AUTOSAR XML (schema 4-3-0)
package /App_CAN_TX
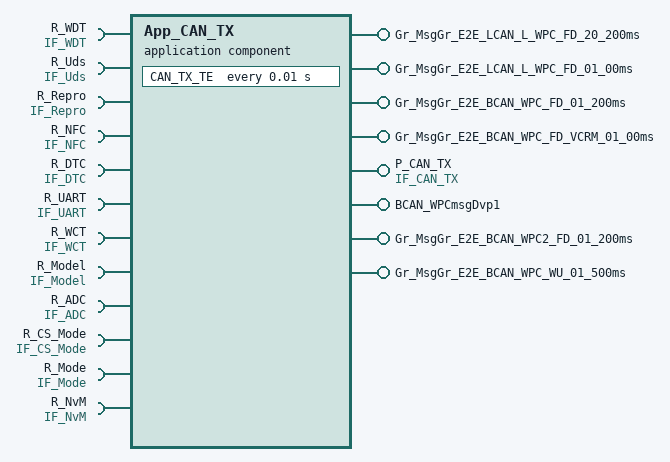
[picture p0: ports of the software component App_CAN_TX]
  application sw component type App_CAN_TX
    11 x require port:
      R_WDT: nonqueued-receiver-com-spec=WDT_STR, required-interface=IF_WDT
      R_Uds: nonqueued-receiver-com-spec=Uds_STR, required-interface=IF_Uds
      R_Repro: nonqueued-receiver-com-spec=Repro_STR, required-interface=IF_Repro
      R_NFC: nonqueued-receiver-com-spec=NFC_STR, required-interface=IF_NFC
      R_DTC: nonqueued-receiver-com-spec=DTC_STR, required-interface=IF_DTC
      R_UART: nonqueued-receiver-com-spec=UART_STR, required-interface=IF_UART
      R_WCT: nonqueued-receiver-com-spec=WCT_STR, required-interface=IF_WCT
      R_Model: nonqueued-receiver-com-spec=Model_STR, required-interface=IF_Model
      R_ADC: nonqueued-receiver-com-spec=ADC_STR, required-interface=IF_ADC
      R_CS_Mode: required-com-specs=[ModeInit, NvMInit, ApplicationInit], required-interface=IF_CS_Mode
      R_Mode: nonqueued-receiver-com-spec=Mode_STR, required-interface=IF_Mode
    6 x provide port:
      Gr_MsgGr_E2E_LCAN_L_WPC_FD_20_200ms: nonqueued-sender-com-spec=data-element=MsgGr_E2E_LCAN_L_WPC_FD_20_200ms, provided-interface=Gr_MsgGr_E2E_LCAN_L_WPC_FD_20_200ms
      Gr_MsgGr_E2E_LCAN_L_WPC_FD_01_00ms: nonqueued-sender-com-spec=data-element=MsgGr_E2E_LCAN_L_WPC_FD_01_00ms, provided-interface=Gr_MsgGr_E2E_LCAN_L_WPC_FD_01_00ms
      Gr_MsgGr_E2E_BCAN_WPC_FD_01_200ms: nonqueued-sender-com-spec=data-element=MsgGr_E2E_BCAN_WPC_FD_01_200ms, provided-interface=Gr_MsgGr_E2E_BCAN_WPC_FD_01_200ms
      Gr_MsgGr_E2E_BCAN_WPC_FD_VCRM_01_00ms: nonqueued-sender-com-spec=data-element=MsgGr_E2E_BCAN_WPC_FD_VCRM_01_00ms, provided-interface=Gr_MsgGr_E2E_BCAN_WPC_FD_VCRM_01_00ms
      P_CAN_TX: provided-interface=IF_CAN_TX
      BCAN_WPCmsgDvp1: provided-interface=BCAN_WPCmsgDvp1
        provided-com-specs:
          data-element=WPCmsgDvp1DataByte09, network-representation=compu-method=ISignal_BCAN_WPCmsgDvp1_WPCmsgDvp1DataByte09
          data-element=WPCmsgDvp1DataByte08, network-representation=compu-method=ISignal_BCAN_WPCmsgDvp1_WPCmsgDvp1DataByte08
          data-element=WPCmsgDvp1DataByte07, network-representation=compu-method=ISignal_BCAN_WPCmsgDvp1_WPCmsgDvp1DataByte07
          data-element=WPCmsgDvp1DataByte06, network-representation=compu-method=ISignal_BCAN_WPCmsgDvp1_WPCmsgDvp1DataByte06
          data-element=WPCmsgDvp1DataByte49, network-representation=compu-method=ISignal_BCAN_WPCmsgDvp1_WPCmsgDvp1DataByte49
          data-element=WPCmsgDvp1DataByte05, network-representation=compu-method=ISignal_BCAN_WPCmsgDvp1_WPCmsgDvp1DataByte05
          data-element=WPCmsgDvp1DataByte51, network-representation=compu-method=ISignal_BCAN_WPCmsgDvp1_WPCmsgDvp1DataByte51
          data-element=WPCmsgDvp1DataByte50, network-representation=compu-method=ISignal_BCAN_WPCmsgDvp1_WPCmsgDvp1DataByte50
          data-element=WPCmsgDvp1DataByte59, network-representation=compu-method=ISignal_BCAN_WPCmsgDvp1_WPCmsgDvp1DataByte59
          data-element=WPCmsgDvp1DataByte15, network-representation=compu-method=ISignal_BCAN_WPCmsgDvp1_WPCmsgDvp1DataByte15
          data-element=WPCmsgDvp1DataByte58, network-representation=compu-method=ISignal_BCAN_WPCmsgDvp1_WPCmsgDvp1DataByte58
          data-element=WPCmsgDvp1DataByte14, network-representation=compu-method=ISignal_BCAN_WPCmsgDvp1_WPCmsgDvp1DataByte14
          data-element=WPCmsgDvp1DataByte57, network-representation=compu-method=ISignal_BCAN_WPCmsgDvp1_WPCmsgDvp1DataByte57
          data-element=WPCmsgDvp1DataByte13, network-representation=compu-method=ISignal_BCAN_WPCmsgDvp1_WPCmsgDvp1DataByte13
          data-element=WPCmsgDvp1DataByte56, network-representation=compu-method=ISignal_BCAN_WPCmsgDvp1_WPCmsgDvp1DataByte56
          data-element=WPCmsgDvp1DataByte12, network-representation=compu-method=ISignal_BCAN_WPCmsgDvp1_WPCmsgDvp1DataByte12
          data-element=WPCmsgDvp1DataByte55, network-representation=compu-method=ISignal_BCAN_WPCmsgDvp1_WPCmsgDvp1DataByte55
          data-element=WPCmsgDvp1DataByte11, network-representation=compu-method=ISignal_BCAN_WPCmsgDvp1_WPCmsgDvp1DataByte11
          data-element=WPCmsgDvp1DataByte54, network-representation=compu-method=ISignal_BCAN_WPCmsgDvp1_WPCmsgDvp1DataByte54
          data-element=WPCmsgDvp1DataByte10, network-representation=compu-method=ISignal_BCAN_WPCmsgDvp1_WPCmsgDvp1DataByte10
          data-element=WPCmsgDvp1DataByte53, network-representation=compu-method=ISignal_BCAN_WPCmsgDvp1_WPCmsgDvp1DataByte53
          data-element=WPCmsgDvp1DataByte52, network-representation=compu-method=ISignal_BCAN_WPCmsgDvp1_WPCmsgDvp1DataByte52
          data-element=WPCmsgDvp1DataByte39, network-representation=compu-method=ISignal_BCAN_WPCmsgDvp1_WPCmsgDvp1DataByte39
          data-element=WPCmsgDvp1DataByte38, network-representation=compu-method=ISignal_BCAN_WPCmsgDvp1_WPCmsgDvp1DataByte38
          data-element=WPCmsgDvp1DataByte40, network-representation=compu-method=ISignal_BCAN_WPCmsgDvp1_WPCmsgDvp1DataByte40
          data-element=WPCmsgDvp1DataByte48, network-representation=compu-method=ISignal_BCAN_WPCmsgDvp1_WPCmsgDvp1DataByte48
          data-element=WPCmsgDvp1DataByte04, network-representation=compu-method=ISignal_BCAN_WPCmsgDvp1_WPCmsgDvp1DataByte04
          data-element=WPCmsgDvp1DataByte47, network-representation=compu-method=ISignal_BCAN_WPCmsgDvp1_WPCmsgDvp1DataByte47
          data-element=WPCmsgDvp1DataByte03, network-representation=compu-method=ISignal_BCAN_WPCmsgDvp1_WPCmsgDvp1DataByte03
          data-element=WPCmsgDvp1DataByte46, network-representation=compu-method=ISignal_BCAN_WPCmsgDvp1_WPCmsgDvp1DataByte46
          data-element=WPCmsgDvp1DataByte02, network-representation=compu-method=ISignal_BCAN_WPCmsgDvp1_WPCmsgDvp1DataByte02
          data-element=WPCmsgDvp1DataByte45, network-representation=compu-method=ISignal_BCAN_WPCmsgDvp1_WPCmsgDvp1DataByte45
          data-element=WPCmsgDvp1DataByte01, network-representation=compu-method=ISignal_BCAN_WPCmsgDvp1_WPCmsgDvp1DataByte01
          data-element=WPCmsgDvp1DataByte44, network-representation=compu-method=ISignal_BCAN_WPCmsgDvp1_WPCmsgDvp1DataByte44
          data-element=WPCmsgDvp1DataByte00, network-representation=compu-method=ISignal_BCAN_WPCmsgDvp1_WPCmsgDvp1DataByte00
          data-element=WPCmsgDvp1DataByte43, network-representation=compu-method=ISignal_BCAN_WPCmsgDvp1_WPCmsgDvp1DataByte43
          data-element=WPCmsgDvp1DataByte42, network-representation=compu-method=ISignal_BCAN_WPCmsgDvp1_WPCmsgDvp1DataByte42
          data-element=WPCmsgDvp1DataByte41, network-representation=compu-method=ISignal_BCAN_WPCmsgDvp1_WPCmsgDvp1DataByte41
          data-element=WPCmsgDvp1DataByte29, network-representation=compu-method=ISignal_BCAN_WPCmsgDvp1_WPCmsgDvp1DataByte29
          data-element=WPCmsgDvp1DataByte28, network-representation=compu-method=ISignal_BCAN_WPCmsgDvp1_WPCmsgDvp1DataByte28
          data-element=WPCmsgDvp1DataByte27, network-representation=compu-method=ISignal_BCAN_WPCmsgDvp1_WPCmsgDvp1DataByte27
          data-element=WPCmsgDvp1DataByte37, network-representation=compu-method=ISignal_BCAN_WPCmsgDvp1_WPCmsgDvp1DataByte37
          data-element=WPCmsgDvp1DataByte36, network-representation=compu-method=ISignal_BCAN_WPCmsgDvp1_WPCmsgDvp1DataByte36
          data-element=WPCmsgDvp1DataByte35, network-representation=compu-method=ISignal_BCAN_WPCmsgDvp1_WPCmsgDvp1DataByte35
          data-element=WPCmsgDvp1DataByte34, network-representation=compu-method=ISignal_BCAN_WPCmsgDvp1_WPCmsgDvp1DataByte34
          data-element=WPCmsgDvp1DataByte33, network-representation=compu-method=ISignal_BCAN_WPCmsgDvp1_WPCmsgDvp1DataByte33
          data-element=WPCmsgDvp1DataByte32, network-representation=compu-method=ISignal_BCAN_WPCmsgDvp1_WPCmsgDvp1DataByte32
          data-element=WPCmsgDvp1DataByte31, network-representation=compu-method=ISignal_BCAN_WPCmsgDvp1_WPCmsgDvp1DataByte31
          data-element=WPCmsgDvp1DataByte30, network-representation=compu-method=ISignal_BCAN_WPCmsgDvp1_WPCmsgDvp1DataByte30
          data-element=WPCmsgDvp1DataByte19, network-representation=compu-method=ISignal_BCAN_WPCmsgDvp1_WPCmsgDvp1DataByte19
          data-element=WPCmsgDvp1DataByte18, network-representation=compu-method=ISignal_BCAN_WPCmsgDvp1_WPCmsgDvp1DataByte18
          data-element=WPCmsgDvp1DataByte17, network-representation=compu-method=ISignal_BCAN_WPCmsgDvp1_WPCmsgDvp1DataByte17
          data-element=WPCmsgDvp1DataByte16, network-representation=compu-method=ISignal_BCAN_WPCmsgDvp1_WPCmsgDvp1DataByte16
          data-element=WPCmsgDvp1DataByte62, network-representation=compu-method=ISignal_BCAN_WPCmsgDvp1_WPCmsgDvp1DataByte62
          data-element=WPCmsgDvp1DataByte61, network-representation=compu-method=ISignal_BCAN_WPCmsgDvp1_WPCmsgDvp1DataByte61
          data-element=WPCmsgDvp1DataByte60, network-representation=compu-method=ISignal_BCAN_WPCmsgDvp1_WPCmsgDvp1DataByte60
          data-element=WPCmsgDvp1DataByte26, network-representation=compu-method=ISignal_BCAN_WPCmsgDvp1_WPCmsgDvp1DataByte26
          data-element=WPCmsgDvp1DataByte25, network-representation=compu-method=ISignal_BCAN_WPCmsgDvp1_WPCmsgDvp1DataByte25
          data-element=WPCmsgDvp1DataByte24, network-representation=compu-method=ISignal_BCAN_WPCmsgDvp1_WPCmsgDvp1DataByte24
          data-element=WPCmsgDvp1DataByte23, network-representation=compu-method=ISignal_BCAN_WPCmsgDvp1_WPCmsgDvp1DataByte23
          data-element=WPCmsgDvp1DataByte22, network-representation=compu-method=ISignal_BCAN_WPCmsgDvp1_WPCmsgDvp1DataByte22
          data-element=WPCmsgDvp1DataByte21, network-representation=compu-method=ISignal_BCAN_WPCmsgDvp1_WPCmsgDvp1DataByte21
          data-element=WPCmsgDvp1DataByte20, network-representation=compu-method=ISignal_BCAN_WPCmsgDvp1_WPCmsgDvp1DataByte20
          data-element=WPCmsgDvp1DataByte63, network-representation=compu-method=ISignal_BCAN_WPCmsgDvp1_WPCmsgDvp1DataByte63
    require port R_NvM: nonqueued-receiver-com-spec=NvM_STR, required-interface=IF_NvM
    provide port Gr_MsgGr_E2E_BCAN_WPC2_FD_01_200ms: nonqueued-sender-com-spec=data-element=MsgGr_E2E_BCAN_WPC2_FD_01_200ms, provided-interface=Gr_MsgGr_E2E_BCAN_WPC2_FD_01_200ms
    provide port Gr_MsgGr_E2E_BCAN_WPC_WU_01_500ms: nonqueued-sender-com-spec=data-element=MsgGr_E2E_BCAN_WPC_WU_01_500ms, provided-interface=Gr_MsgGr_E2E_BCAN_WPC_WU_01_500ms
    behavior InternalBehavior: data-type-mapping=DataTypeMappingSet_WPC
      timing event TE_CAN_TX_TE: start-on-event=CAN_TX_TE, period=0.01
      runnable CAN_TX_TE: symbol=CAN_TX_TE_Runnable
        data-receive-point-by-arguments:
          11 x access, all with scope=COMMUNICATION-INTER-ECU:
            DRPBA_BCAN_TX_TE_R_Mode_Mode_u8_arr: accessed-variable=R_Mode.Mode_STR
            DRPBA_BCAN_TX_TE_R_ADC_u8_arr: accessed-variable=R_ADC.ADC_STR
            DRPBA_BCAN_TX_TE_R_Model_Structure: accessed-variable=R_Model.Model_STR
            DRPBA_BCAN_TX_TE_R_Repro_Structure: accessed-variable=R_Repro.Repro_STR
            DRPBA_BCAN_TX_TE_R_UART_Structure: accessed-variable=R_UART.UART_STR
            DRPBA_CAN_TX_TE_R_NFC_NFC2_STR: accessed-variable=R_NFC.NFC_STR
            DRPBA_CAN_TX_TE_R_WCT_WCT_STR_ALL: accessed-variable=R_WCT.WCT_STR
            DRPBA_CAN_TX_TE_R_DTC_DTC_STR: accessed-variable=R_DTC.DTC_STR
            DRPBA_CAN_TX_TE_R_NvM_NvM_STR: accessed-variable=R_NvM.NvM_STR
            DRPBA_CAN_TX_TE_R_Uds_Uds_STR: accessed-variable=R_Uds.Uds_STR
            DRPBA_CAN_TX_TE_R_WDT_WDT_STR: accessed-variable=R_WDT.WDT_STR
        data-send-points:
          70 x access, all with scope=COMMUNICATION-INTER-ECU:
            DSP_CAN_TX_TE_Gr_MsgGr_E2E_LCAN_L_WPC_FD_20_200ms_MsgGr_E2E_LCAN_L_WPC_FD_20_200ms: accessed-variable=Gr_MsgGr_E2E_LCAN_L_WPC_FD_20_200ms.MsgGr_E2E_LCAN_L_WPC_FD_20_200ms
            DSP_CAN_TX_TE_Gr_MsgGr_E2E_LCAN_L_WPC_FD_01_00ms_MsgGr_E2E_LCAN_L_WPC_FD_01_00ms: accessed-variable=Gr_MsgGr_E2E_LCAN_L_WPC_FD_01_00ms.MsgGr_E2E_LCAN_L_WPC_FD_01_00ms
            DSP_CAN_TX_TE_Gr_MsgGr_E2E_BCAN_WPC_FD_01_200ms_MsgGr_E2E_BCAN_WPC_FD_01_200ms: accessed-variable=Gr_MsgGr_E2E_BCAN_WPC_FD_01_200ms.MsgGr_E2E_BCAN_WPC_FD_01_200ms
            DSP_CAN_TX_TE_Gr_MsgGr_E2E_BCAN_WPC_FD_VCRM_01_00ms_MsgGr_E2E_BCAN_WPC_FD_VCRM_01_00ms: accessed-variable=Gr_MsgGr_E2E_BCAN_WPC_FD_VCRM_01_00ms.MsgGr_E2E_BCAN_WPC_FD_VCRM_01_00ms
            DSP_CAN_TX_TE_BCAN_WPCmsgDvp1_WPCmsgDvp1DataByte09: accessed-variable=BCAN_WPCmsgDvp1.WPCmsgDvp1DataByte09
            DSP_CAN_TX_TE_BCAN_WPCmsgDvp1_WPCmsgDvp1DataByte08: accessed-variable=BCAN_WPCmsgDvp1.WPCmsgDvp1DataByte08
            DSP_CAN_TX_TE_BCAN_WPCmsgDvp1_WPCmsgDvp1DataByte07: accessed-variable=BCAN_WPCmsgDvp1.WPCmsgDvp1DataByte07
            DSP_CAN_TX_TE_BCAN_WPCmsgDvp1_WPCmsgDvp1DataByte06: accessed-variable=BCAN_WPCmsgDvp1.WPCmsgDvp1DataByte06
            DSP_CAN_TX_TE_BCAN_WPCmsgDvp1_WPCmsgDvp1DataByte49: accessed-variable=BCAN_WPCmsgDvp1.WPCmsgDvp1DataByte49
            DSP_CAN_TX_TE_BCAN_WPCmsgDvp1_WPCmsgDvp1DataByte05: accessed-variable=BCAN_WPCmsgDvp1.WPCmsgDvp1DataByte05
            DSP_CAN_TX_TE_BCAN_WPCmsgDvp1_WPCmsgDvp1DataByte51: accessed-variable=BCAN_WPCmsgDvp1.WPCmsgDvp1DataByte51
            DSP_CAN_TX_TE_BCAN_WPCmsgDvp1_WPCmsgDvp1DataByte50: accessed-variable=BCAN_WPCmsgDvp1.WPCmsgDvp1DataByte50
            DSP_CAN_TX_TE_BCAN_WPCmsgDvp1_WPCmsgDvp1DataByte59: accessed-variable=BCAN_WPCmsgDvp1.WPCmsgDvp1DataByte59
            DSP_CAN_TX_TE_BCAN_WPCmsgDvp1_WPCmsgDvp1DataByte15: accessed-variable=BCAN_WPCmsgDvp1.WPCmsgDvp1DataByte15
            DSP_CAN_TX_TE_BCAN_WPCmsgDvp1_WPCmsgDvp1DataByte58: accessed-variable=BCAN_WPCmsgDvp1.WPCmsgDvp1DataByte58
            DSP_CAN_TX_TE_BCAN_WPCmsgDvp1_WPCmsgDvp1DataByte14: accessed-variable=BCAN_WPCmsgDvp1.WPCmsgDvp1DataByte14
            DSP_CAN_TX_TE_BCAN_WPCmsgDvp1_WPCmsgDvp1DataByte57: accessed-variable=BCAN_WPCmsgDvp1.WPCmsgDvp1DataByte57
            DSP_CAN_TX_TE_BCAN_WPCmsgDvp1_WPCmsgDvp1DataByte13: accessed-variable=BCAN_WPCmsgDvp1.WPCmsgDvp1DataByte13
            DSP_CAN_TX_TE_BCAN_WPCmsgDvp1_WPCmsgDvp1DataByte56: accessed-variable=BCAN_WPCmsgDvp1.WPCmsgDvp1DataByte56
            DSP_CAN_TX_TE_BCAN_WPCmsgDvp1_WPCmsgDvp1DataByte12: accessed-variable=BCAN_WPCmsgDvp1.WPCmsgDvp1DataByte12
            DSP_CAN_TX_TE_BCAN_WPCmsgDvp1_WPCmsgDvp1DataByte55: accessed-variable=BCAN_WPCmsgDvp1.WPCmsgDvp1DataByte55
            DSP_CAN_TX_TE_BCAN_WPCmsgDvp1_WPCmsgDvp1DataByte11: accessed-variable=BCAN_WPCmsgDvp1.WPCmsgDvp1DataByte11
            DSP_CAN_TX_TE_BCAN_WPCmsgDvp1_WPCmsgDvp1DataByte54: accessed-variable=BCAN_WPCmsgDvp1.WPCmsgDvp1DataByte54
            DSP_CAN_TX_TE_BCAN_WPCmsgDvp1_WPCmsgDvp1DataByte10: accessed-variable=BCAN_WPCmsgDvp1.WPCmsgDvp1DataByte10
            DSP_CAN_TX_TE_BCAN_WPCmsgDvp1_WPCmsgDvp1DataByte53: accessed-variable=BCAN_WPCmsgDvp1.WPCmsgDvp1DataByte53
            DSP_CAN_TX_TE_BCAN_WPCmsgDvp1_WPCmsgDvp1DataByte52: accessed-variable=BCAN_WPCmsgDvp1.WPCmsgDvp1DataByte52
            DSP_CAN_TX_TE_BCAN_WPCmsgDvp1_WPCmsgDvp1DataByte39: accessed-variable=BCAN_WPCmsgDvp1.WPCmsgDvp1DataByte39
            DSP_CAN_TX_TE_BCAN_WPCmsgDvp1_WPCmsgDvp1DataByte38: accessed-variable=BCAN_WPCmsgDvp1.WPCmsgDvp1DataByte38
            DSP_CAN_TX_TE_BCAN_WPCmsgDvp1_WPCmsgDvp1DataByte40: accessed-variable=BCAN_WPCmsgDvp1.WPCmsgDvp1DataByte40
            DSP_CAN_TX_TE_BCAN_WPCmsgDvp1_WPCmsgDvp1DataByte48: accessed-variable=BCAN_WPCmsgDvp1.WPCmsgDvp1DataByte48
            DSP_CAN_TX_TE_BCAN_WPCmsgDvp1_WPCmsgDvp1DataByte04: accessed-variable=BCAN_WPCmsgDvp1.WPCmsgDvp1DataByte04
            DSP_CAN_TX_TE_BCAN_WPCmsgDvp1_WPCmsgDvp1DataByte47: accessed-variable=BCAN_WPCmsgDvp1.WPCmsgDvp1DataByte47
            DSP_CAN_TX_TE_BCAN_WPCmsgDvp1_WPCmsgDvp1DataByte03: accessed-variable=BCAN_WPCmsgDvp1.WPCmsgDvp1DataByte03
            DSP_CAN_TX_TE_BCAN_WPCmsgDvp1_WPCmsgDvp1DataByte46: accessed-variable=BCAN_WPCmsgDvp1.WPCmsgDvp1DataByte46
            DSP_CAN_TX_TE_BCAN_WPCmsgDvp1_WPCmsgDvp1DataByte02: accessed-variable=BCAN_WPCmsgDvp1.WPCmsgDvp1DataByte02
            DSP_CAN_TX_TE_BCAN_WPCmsgDvp1_WPCmsgDvp1DataByte45: accessed-variable=BCAN_WPCmsgDvp1.WPCmsgDvp1DataByte45
            DSP_CAN_TX_TE_BCAN_WPCmsgDvp1_WPCmsgDvp1DataByte01: accessed-variable=BCAN_WPCmsgDvp1.WPCmsgDvp1DataByte01
            DSP_CAN_TX_TE_BCAN_WPCmsgDvp1_WPCmsgDvp1DataByte44: accessed-variable=BCAN_WPCmsgDvp1.WPCmsgDvp1DataByte44
            DSP_CAN_TX_TE_BCAN_WPCmsgDvp1_WPCmsgDvp1DataByte00: accessed-variable=BCAN_WPCmsgDvp1.WPCmsgDvp1DataByte00
            DSP_CAN_TX_TE_BCAN_WPCmsgDvp1_WPCmsgDvp1DataByte43: accessed-variable=BCAN_WPCmsgDvp1.WPCmsgDvp1DataByte43
            DSP_CAN_TX_TE_BCAN_WPCmsgDvp1_WPCmsgDvp1DataByte42: accessed-variable=BCAN_WPCmsgDvp1.WPCmsgDvp1DataByte42
            DSP_CAN_TX_TE_BCAN_WPCmsgDvp1_WPCmsgDvp1DataByte41: accessed-variable=BCAN_WPCmsgDvp1.WPCmsgDvp1DataByte41
            DSP_CAN_TX_TE_BCAN_WPCmsgDvp1_WPCmsgDvp1DataByte29: accessed-variable=BCAN_WPCmsgDvp1.WPCmsgDvp1DataByte29
            DSP_CAN_TX_TE_BCAN_WPCmsgDvp1_WPCmsgDvp1DataByte28: accessed-variable=BCAN_WPCmsgDvp1.WPCmsgDvp1DataByte28
            DSP_CAN_TX_TE_BCAN_WPCmsgDvp1_WPCmsgDvp1DataByte27: accessed-variable=BCAN_WPCmsgDvp1.WPCmsgDvp1DataByte27
            DSP_CAN_TX_TE_BCAN_WPCmsgDvp1_WPCmsgDvp1DataByte37: accessed-variable=BCAN_WPCmsgDvp1.WPCmsgDvp1DataByte37
            DSP_CAN_TX_TE_BCAN_WPCmsgDvp1_WPCmsgDvp1DataByte36: accessed-variable=BCAN_WPCmsgDvp1.WPCmsgDvp1DataByte36
            DSP_CAN_TX_TE_BCAN_WPCmsgDvp1_WPCmsgDvp1DataByte35: accessed-variable=BCAN_WPCmsgDvp1.WPCmsgDvp1DataByte35
            DSP_CAN_TX_TE_BCAN_WPCmsgDvp1_WPCmsgDvp1DataByte34: accessed-variable=BCAN_WPCmsgDvp1.WPCmsgDvp1DataByte34
            DSP_CAN_TX_TE_BCAN_WPCmsgDvp1_WPCmsgDvp1DataByte33: accessed-variable=BCAN_WPCmsgDvp1.WPCmsgDvp1DataByte33
            DSP_CAN_TX_TE_BCAN_WPCmsgDvp1_WPCmsgDvp1DataByte32: accessed-variable=BCAN_WPCmsgDvp1.WPCmsgDvp1DataByte32
            DSP_CAN_TX_TE_BCAN_WPCmsgDvp1_WPCmsgDvp1DataByte31: accessed-variable=BCAN_WPCmsgDvp1.WPCmsgDvp1DataByte31
            DSP_CAN_TX_TE_BCAN_WPCmsgDvp1_WPCmsgDvp1DataByte30: accessed-variable=BCAN_WPCmsgDvp1.WPCmsgDvp1DataByte30
            DSP_CAN_TX_TE_BCAN_WPCmsgDvp1_WPCmsgDvp1DataByte19: accessed-variable=BCAN_WPCmsgDvp1.WPCmsgDvp1DataByte19
            DSP_CAN_TX_TE_BCAN_WPCmsgDvp1_WPCmsgDvp1DataByte18: accessed-variable=BCAN_WPCmsgDvp1.WPCmsgDvp1DataByte18
            DSP_CAN_TX_TE_BCAN_WPCmsgDvp1_WPCmsgDvp1DataByte17: accessed-variable=BCAN_WPCmsgDvp1.WPCmsgDvp1DataByte17
            DSP_CAN_TX_TE_BCAN_WPCmsgDvp1_WPCmsgDvp1DataByte16: accessed-variable=BCAN_WPCmsgDvp1.WPCmsgDvp1DataByte16
            DSP_CAN_TX_TE_BCAN_WPCmsgDvp1_WPCmsgDvp1DataByte62: accessed-variable=BCAN_WPCmsgDvp1.WPCmsgDvp1DataByte62
            DSP_CAN_TX_TE_BCAN_WPCmsgDvp1_WPCmsgDvp1DataByte61: accessed-variable=BCAN_WPCmsgDvp1.WPCmsgDvp1DataByte61
            DSP_CAN_TX_TE_BCAN_WPCmsgDvp1_WPCmsgDvp1DataByte60: accessed-variable=BCAN_WPCmsgDvp1.WPCmsgDvp1DataByte60
            DSP_CAN_TX_TE_BCAN_WPCmsgDvp1_WPCmsgDvp1DataByte26: accessed-variable=BCAN_WPCmsgDvp1.WPCmsgDvp1DataByte26
            DSP_CAN_TX_TE_BCAN_WPCmsgDvp1_WPCmsgDvp1DataByte25: accessed-variable=BCAN_WPCmsgDvp1.WPCmsgDvp1DataByte25
            DSP_CAN_TX_TE_BCAN_WPCmsgDvp1_WPCmsgDvp1DataByte24: accessed-variable=BCAN_WPCmsgDvp1.WPCmsgDvp1DataByte24
            DSP_CAN_TX_TE_BCAN_WPCmsgDvp1_WPCmsgDvp1DataByte23: accessed-variable=BCAN_WPCmsgDvp1.WPCmsgDvp1DataByte23
            DSP_CAN_TX_TE_BCAN_WPCmsgDvp1_WPCmsgDvp1DataByte22: accessed-variable=BCAN_WPCmsgDvp1.WPCmsgDvp1DataByte22
            DSP_CAN_TX_TE_BCAN_WPCmsgDvp1_WPCmsgDvp1DataByte21: accessed-variable=BCAN_WPCmsgDvp1.WPCmsgDvp1DataByte21
            DSP_CAN_TX_TE_BCAN_WPCmsgDvp1_WPCmsgDvp1DataByte20: accessed-variable=BCAN_WPCmsgDvp1.WPCmsgDvp1DataByte20
            DSP_CAN_TX_TE_BCAN_WPCmsgDvp1_WPCmsgDvp1DataByte63: accessed-variable=BCAN_WPCmsgDvp1.WPCmsgDvp1DataByte63
            DSP_CAN_TX_TE_Gr_MsgGr_E2E_BCAN_WPC2_FD_01_200ms_MsgGr_E2E_BCAN_WPC2_FD_01_200ms: accessed-variable=Gr_MsgGr_E2E_BCAN_WPC2_FD_01_200ms.MsgGr_E2E_BCAN_WPC2_FD_01_200ms
            DSP_CAN_TX_TE_Gr_MsgGr_E2E_BCAN_WPC_WU_01_500ms_MsgGr_E2E_BCAN_WPC_WU_01_500ms: accessed-variable=Gr_MsgGr_E2E_BCAN_WPC_WU_01_500ms.MsgGr_E2E_BCAN_WPC_WU_01_500ms
        sync call SSCP_BCAN_TX_TE_R_CS_Mode_ApplicationInit: operation=R_CS_Mode.ApplicationInit
        sync call SSCP_BCAN_TX_TE_R_CS_Mode_ModeInit: operation=R_CS_Mode.ModeInit
        sync call SSCP_BCAN_TX_TE_R_CS_Mode_NvMInit: operation=R_CS_Mode.NvMInit
  sender receiver interface IF_CAN_TX  # NFC SWC Output
    data Unused: type=IDT_uint8
